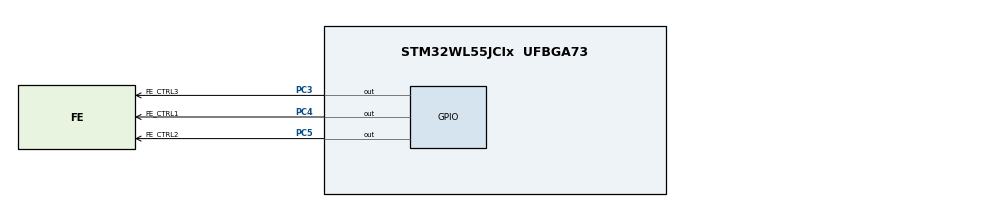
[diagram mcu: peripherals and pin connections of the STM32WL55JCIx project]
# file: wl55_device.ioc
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ADC.ClockPrescaler=ADC_CLOCK_SYNC_PCLK_DIV4
ADC.NbrOfConversion=1
ADC.Overrun=ADC_OVR_DATA_OVERWRITTEN
ADC.SamplingTimeCommon1=ADC_SAMPLETIME_160CYCLES_5
ADC.SamplingTimeCommon2=ADC_SAMPLETIME_160CYCLES_5
ADC.SelectedChannel=ADC_CHANNEL_TEMPSENSOR|ADC_CHANNEL_VREFINT
Mcu.Family=STM32WL
Mcu.Name=STM32WL55JCIx
Mcu.Package=UFBGA73
NUCLEO-WL55JC1.BUTTON=1
NUCLEO-WL55JC1.BUTTON2=1
NUCLEO-WL55JC1.BUTTON3=1
NUCLEO-WL55JC1.LD1=true
NUCLEO-WL55JC1.LD2=true
NUCLEO-WL55JC1.LD3=true
NUCLEO-WL55JC1.VCP=true
NVIC.EXTI0_IRQn=true\:0\:0\:false\:false\:true\:false\:true\:true
NVIC.EXTI1_IRQn=true\:0\:0\:false\:false\:true\:false\:true\:true
NVIC.EXTI9_5_IRQn=true\:0\:0\:false\:false\:true\:false\:true\:true
NVIC.PriorityGroup=NVIC_PRIORITYGROUP_4
NVIC.TIM2_IRQn=true\:0\:0\:false\:false\:true\:true\:true\:true
PA13.Mode=Serial_Wire
PA13.Signal=DEBUG_JTMS-SWDIO
PA14.Mode=Serial_Wire
PA14.Signal=DEBUG_JTCK-SWCLK
PA2.Signal=LPUART1_TX
PA3.Signal=LPUART1_RX
PC14-OSC32_IN.GPIO_Label=RCC_OSC32_IN
PC14-OSC32_IN.Signal=RCC_OSC32_IN
PC15-OSC32_OUT.GPIO_Label=RCC_OSC32_OUT
PC15-OSC32_OUT.Signal=RCC_OSC32_OUT
PC3.GPIO_Label=FE_CTRL3
PC3.GPIO_Speed=GPIO_SPEED_FREQ_VERY_HIGH
PC3.Signal=GPIO_Output
PC4.GPIO_Label=FE_CTRL1
PC4.GPIO_Speed=GPIO_SPEED_FREQ_VERY_HIGH
PC4.Signal=GPIO_Output
PC5.GPIO_Label=FE_CTRL2
PC5.GPIO_Speed=GPIO_SPEED_FREQ_VERY_HIGH
PC5.Signal=GPIO_Output
ProjectManager.HeapSize=0x200
ProjectManager.StackSize=0x400
ProjectManager.TargetToolchain=CMake
RCC.AHBFreq_Value=48000000
RCC.APB1Freq_Value=48000000
RCC.APB1TimFreq_Value=48000000
RCC.APB2Freq_Value=48000000
RCC.APB2TimFreq_Value=48000000
RCC.APB3Freq_Value=48000000
RCC.CortexFreq_Value=48000000
RCC.HCLKFreq_Value=48000000
RCC.HSE_VALUE=32000000
RCC.HSI_VALUE=16000000
RCC.LSE_VALUE=32768
RCC.MSIClockRange=RCC_MSIRANGE_11
RCC.RNGCLockSelection=RCC_RNGCLKSOURCE_MSI
RCC.SYSCLKFreq_VALUE=48000000
RCC.VCOOutputFreq_Value=384000000
TIM2.AutoReloadPreload=TIM_AUTORELOAD_PRELOAD_DISABLE
TIM2.Period=4294967295
TIM2.Prescaler=47
VP_ADC_TempSens_Input.Mode=IN-TempSens
VP_ADC_Vref_Input.Mode=IN-Vrefint
VP_AES_VS_AES.Mode=AES_Activate
VP_NUCLEO-WL55JC1_VS_BSP_COMMON.Mode=COMMON
VP_PKA_VS_PKA.Mode=PKA_Activate
VP_RNG_VS_RNG.Mode=RNG_Activate
VP_SUBGHZ_VS_SUBGHZ.Mode=SUBGHZ_Activate
VP_TIM2_VS_ClockSourceINT.Mode=Internal
board=NUCLEO-WL55JC1

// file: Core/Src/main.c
/* USER CODE BEGIN Header */
/**
  ******************************************************************************
  * @file           : main.c
  * @brief          : Main program body
  ******************************************************************************
  * @attention
  *
  * Copyright (c) 2026 STMicroelectronics.
  * All rights reserved.
  *
  * This software is licensed under terms that can be found in the LICENSE file
  * in the root directory of this software component.
  * If no LICENSE file comes with this software, it is provided AS-IS.
  *
  ******************************************************************************
  */
/* USER CODE END Header */
#include "main.h"

/* USER CODE BEGIN Includes */
#include "load.h"
#include "console.h"
#include "device.h"
#include "hublogic.h"
#include "radio.h"
#include "sensor.h"
#include "clock.h"
/* USER CODE END Includes */

COM_InitTypeDef BspCOMInit;
ADC_HandleTypeDef hadc;

CRYP_HandleTypeDef hcryp;
__ALIGN_BEGIN static const uint32_t pKeyAES[4] __ALIGN_END = {
                            0x00000000,0x00000000,0x00000000,0x00000000};

PKA_HandleTypeDef hpka;

RNG_HandleTypeDef hrng;

SUBGHZ_HandleTypeDef hsubghz;

TIM_HandleTypeDef htim2;

void SystemClock_Config(void);
static void MX_GPIO_Init(void);
static void MX_TIM2_Init(void);
static void MX_SUBGHZ_Init(void);
static void MX_RNG_Init(void);
static void MX_AES_Init(void);
static void MX_PKA_Init(void);
static void MX_ADC_Init(void);

int main(void)
{

  /* MCU Configuration--------------------------------------------------------*/

  /* Reset of all peripherals, Initializes the Flash interface and the Systick. */
  HAL_Init();

  /* Configure the system clock */
  SystemClock_Config();

  /* Initialize all configured peripherals */
  MX_GPIO_Init();
  MX_TIM2_Init();
  MX_SUBGHZ_Init();
  MX_RNG_Init();
  MX_AES_Init();
  MX_PKA_Init();
  MX_ADC_Init();
  /* USER CODE BEGIN 2 */
  timebase_start();
  load_reset();
  /* Park the radio in standby so its status byte is meaningful straight away. */
  radio_standby();
  /* USER CODE END 2 */

  /* Initialize leds */
  BSP_LED_Init(LED_BLUE);
  BSP_LED_Init(LED_GREEN);
  BSP_LED_Init(LED_RED);

  /* Initialize USER push-button, will be used to trigger an interrupt each time it's pressed.*/
  BSP_PB_Init(BUTTON_SW1, BUTTON_MODE_EXTI);
  BSP_PB_Init(BUTTON_SW2, BUTTON_MODE_EXTI);
  BSP_PB_Init(BUTTON_SW3, BUTTON_MODE_EXTI);

  /* Initialize COM1 port (115200, 8 bits (7-bit data + 1 stop bit), no parity */
  BspCOMInit.BaudRate   = 115200;
  BspCOMInit.WordLength = COM_WORDLENGTH_8B;
  BspCOMInit.StopBits   = COM_STOPBITS_1;
  BspCOMInit.Parity     = COM_PARITY_NONE;
  BspCOMInit.HwFlowCtl  = COM_HWCONTROL_NONE;
  if (BSP_COM_Init(COM1, &BspCOMInit) != BSP_ERROR_NONE)
  {
    Error_Handler();
  }

  /* Infinite loop */
  /* USER CODE BEGIN WHILE */
  /* After the generated BSP_COM_Init above, which re-initialises the same UART. */
#if WL55_ROLE_HUB
  hub_init();
#else
  device_init();
#endif
  console_init();
  extern volatile uint32_t loop_mark;
  extern volatile uint32_t loop_beat;
  while (1)
  {

    /* USER CODE END WHILE */

    /* USER CODE BEGIN 3 */
    loop_mark = 0x11u;
    console_poll();
    loop_mark = 0x12u;
    timebase_service();
    loop_mark = 0x13u;
#if WL55_ROLE_HUB
    hub_service();
#else
    device_service();
#endif
    loop_mark = 0x14u;
    sensor_service();
    loop_mark = 0x15u;
    telemetry_service();
    loop_beat++;
  }
  /* USER CODE END 3 */
}

void SystemClock_Config(void)
{
  RCC_OscInitTypeDef RCC_OscInitStruct = {0};
  RCC_ClkInitTypeDef RCC_ClkInitStruct = {0};

  /** Configure the main internal regulator output voltage
  */
  __HAL_PWR_VOLTAGESCALING_CONFIG(PWR_REGULATOR_VOLTAGE_SCALE1);

  /** Initializes the CPU, AHB and APB buses clocks
  */
  RCC_OscInitStruct.OscillatorType = RCC_OSCILLATORTYPE_MSI;
  RCC_OscInitStruct.MSIState = RCC_MSI_ON;
  RCC_OscInitStruct.MSICalibrationValue = RCC_MSICALIBRATION_DEFAULT;
  RCC_OscInitStruct.MSIClockRange = RCC_MSIRANGE_11;
  RCC_OscInitStruct.PLL.PLLState = RCC_PLL_NONE;
  if (HAL_RCC_OscConfig(&RCC_OscInitStruct) != HAL_OK)
  {
    Error_Handler();
  }

  /** Configure the SYSCLKSource, HCLK, PCLK1 and PCLK2 clocks dividers
  */
  RCC_ClkInitStruct.ClockType = RCC_CLOCKTYPE_HCLK3|RCC_CLOCKTYPE_HCLK
                              |RCC_CLOCKTYPE_SYSCLK|RCC_CLOCKTYPE_PCLK1
                              |RCC_CLOCKTYPE_PCLK2;
  RCC_ClkInitStruct.SYSCLKSource = RCC_SYSCLKSOURCE_MSI;
  RCC_ClkInitStruct.AHBCLKDivider = RCC_SYSCLK_DIV1;
  RCC_ClkInitStruct.APB1CLKDivider = RCC_HCLK_DIV1;
  RCC_ClkInitStruct.APB2CLKDivider = RCC_HCLK_DIV1;
  RCC_ClkInitStruct.AHBCLK3Divider = RCC_SYSCLK_DIV1;

  if (HAL_RCC_ClockConfig(&RCC_ClkInitStruct, FLASH_LATENCY_2) != HAL_OK)
  {
    Error_Handler();
  }
}

static void MX_ADC_Init(void)
{

  /** Configure the global features of the ADC (Clock, Resolution, Data Alignment and number of conversion)
  */
  hadc.Instance = ADC;
  hadc.Init.ClockPrescaler = ADC_CLOCK_SYNC_PCLK_DIV4;
  hadc.Init.Resolution = ADC_RESOLUTION_12B;
  hadc.Init.DataAlign = ADC_DATAALIGN_RIGHT;
  hadc.Init.ScanConvMode = ADC_SCAN_DISABLE;
  hadc.Init.EOCSelection = ADC_EOC_SINGLE_CONV;
  hadc.Init.LowPowerAutoWait = DISABLE;
  hadc.Init.LowPowerAutoPowerOff = DISABLE;
  hadc.Init.ContinuousConvMode = DISABLE;
  hadc.Init.NbrOfConversion = 1;
  hadc.Init.DiscontinuousConvMode = DISABLE;
  hadc.Init.ExternalTrigConv = ADC_SOFTWARE_START;
  hadc.Init.ExternalTrigConvEdge = ADC_EXTERNALTRIGCONVEDGE_NONE;
  hadc.Init.DMAContinuousRequests = DISABLE;
  hadc.Init.Overrun = ADC_OVR_DATA_OVERWRITTEN;
  hadc.Init.SamplingTimeCommon1 = ADC_SAMPLETIME_160CYCLES_5;
  hadc.Init.SamplingTimeCommon2 = ADC_SAMPLETIME_160CYCLES_5;
  hadc.Init.OversamplingMode = DISABLE;
  hadc.Init.TriggerFrequencyMode = ADC_TRIGGER_FREQ_HIGH;
  if (HAL_ADC_Init(&hadc) != HAL_OK)
  {
    Error_Handler();
  }

}

static void MX_AES_Init(void)
{

  hcryp.Instance = AES;
  hcryp.Init.DataType = CRYP_DATATYPE_32B;
  hcryp.Init.KeySize = CRYP_KEYSIZE_128B;
  hcryp.Init.pKey = (uint32_t *)pKeyAES;
  hcryp.Init.Algorithm = CRYP_AES_ECB;
  hcryp.Init.DataWidthUnit = CRYP_DATAWIDTHUNIT_WORD;
  hcryp.Init.HeaderWidthUnit = CRYP_HEADERWIDTHUNIT_WORD;
  hcryp.Init.KeyIVConfigSkip = CRYP_KEYIVCONFIG_ALWAYS;
  if (HAL_CRYP_Init(&hcryp) != HAL_OK)
  {
    Error_Handler();
  }

}

static void MX_PKA_Init(void)
{

  hpka.Instance = PKA;
  if (HAL_PKA_Init(&hpka) != HAL_OK)
  {
    Error_Handler();
  }

}

static void MX_RNG_Init(void)
{

  hrng.Instance = RNG;
  hrng.Init.ClockErrorDetection = RNG_CED_ENABLE;
  if (HAL_RNG_Init(&hrng) != HAL_OK)
  {
    Error_Handler();
  }

}

static void MX_SUBGHZ_Init(void)
{

  hsubghz.Init.BaudratePrescaler = SUBGHZSPI_BAUDRATEPRESCALER_8;
  if (HAL_SUBGHZ_Init(&hsubghz) != HAL_OK)
  {
    Error_Handler();
  }

}

static void MX_TIM2_Init(void)
{

  TIM_ClockConfigTypeDef sClockSourceConfig = {0};
  TIM_MasterConfigTypeDef sMasterConfig = {0};

  htim2.Instance = TIM2;
  htim2.Init.Prescaler = 47;
  htim2.Init.CounterMode = TIM_COUNTERMODE_UP;
  htim2.Init.Period = 4294967295;
  htim2.Init.ClockDivision = TIM_CLOCKDIVISION_DIV1;
  htim2.Init.AutoReloadPreload = TIM_AUTORELOAD_PRELOAD_DISABLE;
  if (HAL_TIM_Base_Init(&htim2) != HAL_OK)
  {
    Error_Handler();
  }
  sClockSourceConfig.ClockSource = TIM_CLOCKSOURCE_INTERNAL;
  if (HAL_TIM_ConfigClockSource(&htim2, &sClockSourceConfig) != HAL_OK)
  {
    Error_Handler();
  }
  sMasterConfig.MasterOutputTrigger = TIM_TRGO_RESET;
  sMasterConfig.MasterSlaveMode = TIM_MASTERSLAVEMODE_DISABLE;
  if (HAL_TIMEx_MasterConfigSynchronization(&htim2, &sMasterConfig) != HAL_OK)
  {
    Error_Handler();
  }

}

static void MX_GPIO_Init(void)
{
  GPIO_InitTypeDef GPIO_InitStruct = {0};

  /* GPIO Ports Clock Enable */
  __HAL_RCC_GPIOA_CLK_ENABLE();
  __HAL_RCC_GPIOC_CLK_ENABLE();

  /*Configure GPIO pin Output Level */
  HAL_GPIO_WritePin(GPIOC, FE_CTRL3_Pin|FE_CTRL2_Pin|FE_CTRL1_Pin, GPIO_PIN_RESET);

  /*Configure GPIO pins : FE_CTRL3_Pin FE_CTRL2_Pin FE_CTRL1_Pin */
  GPIO_InitStruct.Pin = FE_CTRL3_Pin|FE_CTRL2_Pin|FE_CTRL1_Pin;
  GPIO_InitStruct.Mode = GPIO_MODE_OUTPUT_PP;
  GPIO_InitStruct.Pull = GPIO_NOPULL;
  GPIO_InitStruct.Speed = GPIO_SPEED_FREQ_VERY_HIGH;
  HAL_GPIO_Init(GPIOC, &GPIO_InitStruct);

}

void Error_Handler(void)
{
  __disable_irq();
  while (1)
  {
  }
}
#ifdef USE_FULL_ASSERT
/**
  * @brief  Reports the name of the source file and the source line number
  *         where the assert_param error has occurred.
  * @param  file: pointer to the source file name
  * @param  line: assert_param error line source number
  * @retval None
  */
void assert_failed(uint8_t *file, uint32_t line)
{
  /* USER CODE BEGIN 6 */
  /* Nothing is wired up to receive this: the build does not define USE_FULL_ASSERT. */
  (void)file;
  (void)line;
  /* USER CODE END 6 */
}
#endif /* USE_FULL_ASSERT */
